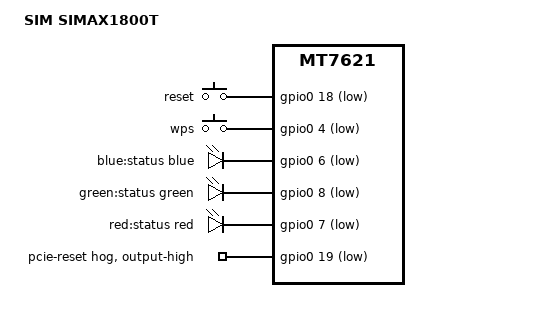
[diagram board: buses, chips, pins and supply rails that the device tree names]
// SPDX-License-Identifier: GPL-2.0-or-later

/dts-v1/;

#include "mt7621.dtsi"

#include <dt-bindings/gpio/gpio.h>
#include <dt-bindings/input/input.h>
#include <dt-bindings/leds/common.h>

/ {
	compatible = "sim,simax1800t", "mediatek,mt7621-soc";
	model = "SIM SIMAX1800T";

	aliases {
		button-boot1 = &key_reset;
		button-boot2 = &key_wps;
		led-status1 = &led_green;
		led-status2 = &led_red;
		serial0 = &uart0;
	};

	chosen {
		stdout-path = &uart0;
	};

	config {
		button-reset-env;
	};

	gpio-keys {
		compatible = "gpio-keys";

		key_reset: reset {
			label = "reset";
			gpios = <&gpio0 18 GPIO_ACTIVE_LOW>;
			linux,code = <KEY_RESTART>;
		};

		key_wps: wps {
			label = "wps";
			gpios = <&gpio0 4 GPIO_ACTIVE_LOW>;
			linux,code = <KEY_WPS_BUTTON>;
		};
	};

	gpio-leds {
		compatible = "gpio-leds";

		led-blue {
			label = "blue:status";
			color = <LED_COLOR_ID_BLUE>;
			function = LED_FUNCTION_STATUS;
			gpios = <&gpio0 6 GPIO_ACTIVE_LOW>;
			default-state = "off";
		};

		led_green: led-green {
			label = "green:status";
			color = <LED_COLOR_ID_GREEN>;
			function = LED_FUNCTION_STATUS;
			gpios = <&gpio0 8 GPIO_ACTIVE_LOW>;
			default-state = "on";
		};

		led_red: led-red {
			label = "red:status";
			color = <LED_COLOR_ID_RED>;
			function = LED_FUNCTION_STATUS;
			gpios = <&gpio0 7 GPIO_ACTIVE_LOW>;
			default-state = "off";
		};
	};
};

&gpio0 {
	pcie-reset {
		gpio-hog;
		gpios = <19 GPIO_ACTIVE_LOW>;
		output-high;
	};
};

&state_default {
	/delete-node/ rgmii2-gpio_pins;
	/delete-node/ sdxc-gpio_pins;
};
